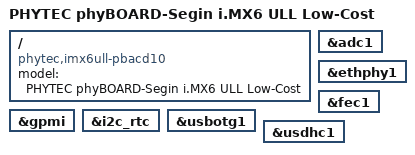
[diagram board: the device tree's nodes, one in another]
/*
 * Copyright (C) 2017 PHYTEC Messtechnik GmbH
 * Author: Stefan Riedmueller <s.riedmueller@phytec.de>
 *
 * This program is free software; you can redistribute it and/or modify
 * it under the terms of the GNU General Public License version 2 as
 * published by the Free Software Foundation.
 */

/dts-v1/;
#include <dt-bindings/input/input.h>
#include "imx6ull.dtsi"
#include "imx6ull-phytec-phycore-som.dtsi"
#include "imx6ull-phytec-segin.dtsi"
#include "imx6ull-phytec-segin-peb-eval-01.dtsi"

/ {

	model = "PHYTEC phyBOARD-Segin i.MX6 ULL Low-Cost";
	compatible = "phytec,imx6ull-pbacd10", "phytec,imx6ull-pcl063","fsl,imx6ull";
};

&adc1 {
	status = "okay";
};

&ethphy1 {
	status = "okay";
};

&fec1 {
	status = "okay";
};

&gpmi {
	status = "okay";
};

&i2c_rtc {
	status = "okay";
};

&usbotg1 {
	status = "okay";
};

&usdhc1 {
	status = "okay";
};
